# GD32H71x_72x register map
File version: 1.0
CPU: CM7 r1p2, little endian, MPU, FPU, 4 interrupt priority bits
Registers are 32-bit, read-write, reset 0x0 unless marked. A register's access mark holds for its fields unless they carry their own. Offsets are from the block's base; [hi:lo] are bit positions.

## ENET0_MAC — Ethernet: media access control
Base 0x40028000
Same registers: ENET1_MAC 0x4002A000
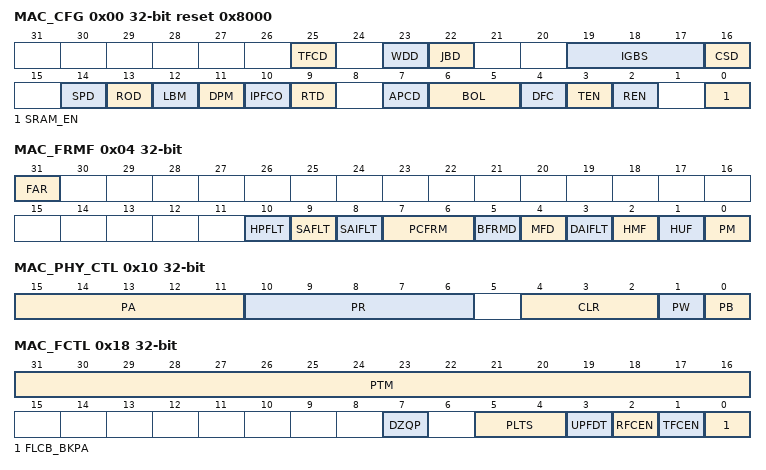
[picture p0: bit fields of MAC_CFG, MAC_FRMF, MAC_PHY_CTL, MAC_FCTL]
0x00 MAC_CFG reset 0x8000 — Ethernet MAC configuration register (MAC_CFG)
  [25] TFCD — Type Frame CRC Dropping
  [23] WDD — Watchdog disable
  [22] JBD — Jabber disable
  [19:17] IGBS — Inter frame gap bit selection
  [16] CSD — Carrier sense disable
  [14] SPD — Fast Ethernet speed
  [13] ROD — Receive own disable
  [12] LBM — Loopback mode
  [11] DPM — Duplex mode
  [10] IPFCO — IP frame checksum offload
  [9] RTD — Retry disable
  [7] APCD — Automatic pad/CRC drop
  [6:5] BOL — Back-off limit
  [4] DFC — Deferral check
  [3] TEN — Transmitter enable
  [2] REN — Receiver enable
  [0] SRAM_EN — Enable the internal SRAM
0x04 MAC_FRMF — Ethernet MAC frame filter register (MAC_FRMF)
  [31] FAR — Frames all receive
  [10] HPFLT — Hash or perfect filter
  [9] SAFLT — Source address filter
  [8] SAIFLT — Source address inverse filtering
  [7:6] PCFRM — Pass control frames
  [5] BFRMD — Broadcast frames disable
  [4] MFD — multicast filter disable
  [3] DAIFLT — Destination address inverse filtering
  [2] HMF — Hash multicast filter
  [1] HUF — Hash unicast filter
  [0] PM — Promiscuous mode
0x08 MAC_HLH — Ethernet MAC hash list high register
  [31:0] HLH — Hash list high
0x0C MAC_HLL — Ethernet MAC hash list low register
  [31:0] HLL — Hash list low
0x10 MAC_PHY_CTL — Ethernet MAC PHY control register (MAC_PHY_CTL)
  [15:11] PA — PHY address
  [10:6] PR — PHY register
  [4:2] CLR — Clock range
  [1] PW — PHY write
  [0] PB — PHY busy
0x14 MAC_PHY_DATA — Ethernet MAC MII data register (MAC_PHY_DATA)
  [15:0] PD — PHY data
0x18 MAC_FCTL — Ethernet MAC flow control register (MAC_FCTL)
  [31:16] PTM — Pause time
  [7] DZQP — Disable Zero-quanta pause
  [5:4] PLTS — Pause low threshold
  [3] UPFDT — Unicast pause frame detect
  [2] RFCEN — Receive flow control enable
  [1] TFCEN — Transmit flow control enable
  [0] FLCB_BKPA — Flow control busy/back pressure activate
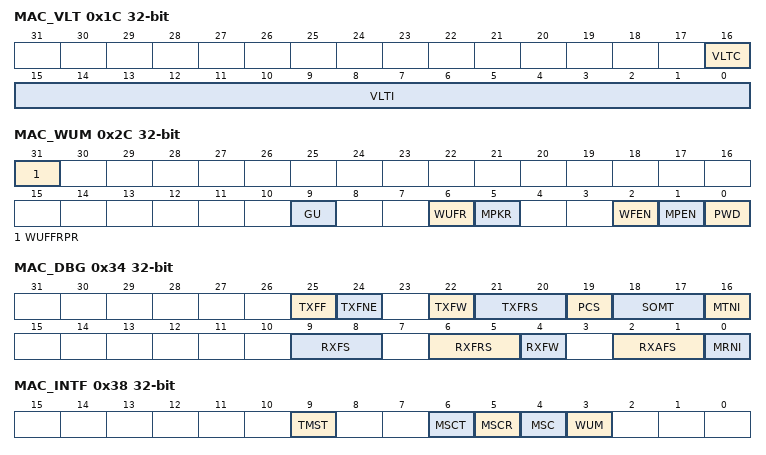
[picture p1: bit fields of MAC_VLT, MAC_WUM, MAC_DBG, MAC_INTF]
0x1C MAC_VLT — Ethernet MAC VLAN tag register (MAC_VLT)
  [16] VLTC — 12-bit VLAN tag comparison
  [15:0] VLTI — VLAN tag identifier (for receive frames)
0x28 MAC_RWFF — Ethernet MAC remote wakeup frame filter register (MAC_RWFF)
0x2C MAC_WUM — Ethernet MAC wakeup management register (MAC_WUM)
  [31] WUFFRPR — Wakeup frame filter register pointer reset
  [9] GU — Global unicast
  [6] WUFR — Wakeup frame received
  [5] MPKR — Magic packet received
  [2] WFEN — Wakeup frame enable
  [1] MPEN — Magic Packet enable
  [0] PWD — Power down
0x34 MAC_DBG ro — Ethernet MAC debug register (MAC_DBG)
  [25] TXFF — TxFIFO Full flag
  [24] TXFNE — TxFIFO not empty flag
  [22] TXFW — TxFIFO is writing
  [21:20] TXFRS — TxFIFO read operation status
  [19] PCS — Pause condition status
  [18:17] SOMT — Status of MAC transmitter
  [16] MTNI — MAC transmit state not idle
  [9:8] RXFS — RxFIFO state
  [6:5] RXFRS — RxFIFO read operation status
  [4] RXFW — RxFIFO is writing
  [2:1] RXAFS — Rx asynchronous FIFO status
  [0] MRNI — MAC receive state not idle
0x38 MAC_INTF ro — Ethernet MAC interrupt flag register (MAC_INTF)
  [9] TMST — Time stamp trigger status
  [6] MSCT — MSC transmit status
  [5] MSCR — MSC receive status
  [4] MSC — MSC status
  [3] WUM — WUM status
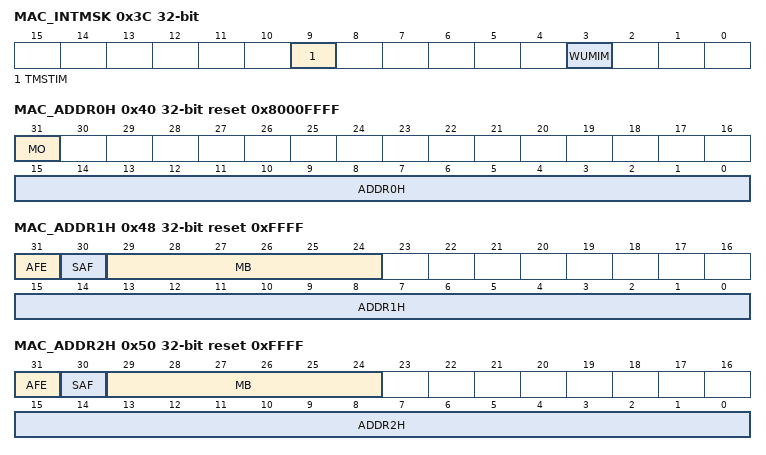
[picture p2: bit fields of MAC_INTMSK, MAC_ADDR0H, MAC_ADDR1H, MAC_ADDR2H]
0x3C MAC_INTMSK — Ethernet MAC interrupt mask register (MAC_INTMSK)
  [9] TMSTIM — Time stamp trigger interrupt mask
  [3] WUMIM — WUM interrupt mask
0x40 MAC_ADDR0H reset 0x8000FFFF — Ethernet MAC address 0 high register (MAC_ADDR0H)
  [31] MO — Always 1
  [15:0] ADDR0H — MAC address0 high
0x44 MAC_ADDR0L reset 0xFFFFFFFF — Ethernet MAC address 0 low register
  [31:0] ADDR0L — MAC address0 low
0x48 MAC_ADDR1H reset 0xFFFF — Ethernet MAC address 1 high register (MAC_ADDR1H)
  [31] AFE — Address filter enable
  [30] SAF — Source address filter
  [29:24] MB — Mask byte
  [15:0] ADDR1H — MAC address1 high
0x4C MAC_ADDR1L reset 0xFFFFFFFF — Ethernet MAC address1 low register
  [31:0] ADDR1L — MAC address1 low
0x50 MAC_ADDR2H reset 0xFFFF — Ethernet MAC address 2 high register (MAC_ADDR2H)
  [31] AFE — Address filter enable
  [30] SAF — Source address filter
  [29:24] MB — Mask byte
  [15:0] ADDR2H — Ethernet MAC address 2 high register
0x54 MAC_ADDR2L reset 0xFFFFFFFF — Ethernet MAC address 2 low register
  [31:0] ADDR2L — MAC address2 low
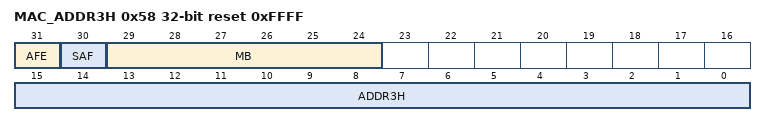
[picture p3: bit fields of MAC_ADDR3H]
0x58 MAC_ADDR3H reset 0xFFFF — Ethernet MAC address 3 high register (MAC_ADDR3H)
  [31] AFE — Address filter enable
  [30] SAF — Source address filter
  [29:24] MB — Mask byte
  [15:0] ADDR3H — MAC address3 high
0x5C MAC_ADDR3L reset 0xFFFFFFFF — Ethernet MAC address 3 low register
  [31:0] ADDR3L — MAC address3 low
